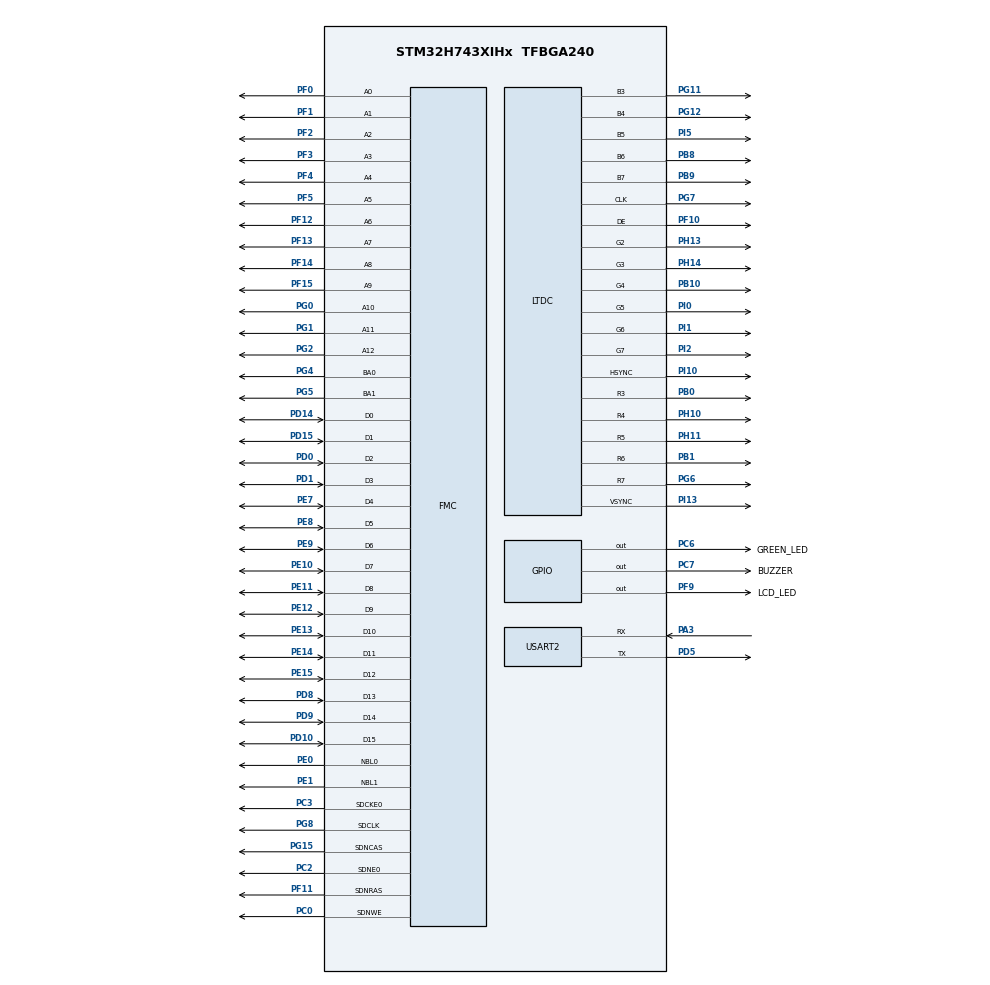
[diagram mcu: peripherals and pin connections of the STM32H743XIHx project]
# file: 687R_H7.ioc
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CORTEX_M7.AccessPermission-Cortex_Memory_Protection_Unit_Region1_Settings=MPU_REGION_FULL_ACCESS
CORTEX_M7.AccessPermission-Cortex_Memory_Protection_Unit_Region2_Settings=MPU_REGION_FULL_ACCESS
CORTEX_M7.AccessPermission-Cortex_Memory_Protection_Unit_Region3_Settings=MPU_REGION_FULL_ACCESS
CORTEX_M7.AccessPermission-Cortex_Memory_Protection_Unit_Region4_Settings=MPU_REGION_FULL_ACCESS
CORTEX_M7.BaseAddress-Cortex_Memory_Protection_Unit_Region1_Settings=0x30020000
CORTEX_M7.BaseAddress-Cortex_Memory_Protection_Unit_Region2_Settings=0x30040000
CORTEX_M7.BaseAddress-Cortex_Memory_Protection_Unit_Region3_Settings=0x60000000
CORTEX_M7.BaseAddress-Cortex_Memory_Protection_Unit_Region4_Settings=0x90000000
CORTEX_M7.CPU_DCache=Enabled
CORTEX_M7.CPU_ICache=Enabled
CORTEX_M7.DisableExec-Cortex_Memory_Protection_Unit_Region0_Settings=MPU_INSTRUCTION_ACCESS_DISABLE
CORTEX_M7.DisableExec-Cortex_Memory_Protection_Unit_Region1_Settings=MPU_INSTRUCTION_ACCESS_DISABLE
CORTEX_M7.DisableExec-Cortex_Memory_Protection_Unit_Region2_Settings=MPU_INSTRUCTION_ACCESS_DISABLE
CORTEX_M7.DisableExec-Cortex_Memory_Protection_Unit_Region3_Settings=MPU_INSTRUCTION_ACCESS_DISABLE
CORTEX_M7.Enable-Cortex_Memory_Protection_Unit_Region0_Settings=MPU_REGION_ENABLE
CORTEX_M7.Enable-Cortex_Memory_Protection_Unit_Region1_Settings=MPU_REGION_ENABLE
CORTEX_M7.Enable-Cortex_Memory_Protection_Unit_Region2_Settings=MPU_REGION_ENABLE
CORTEX_M7.Enable-Cortex_Memory_Protection_Unit_Region3_Settings=MPU_REGION_ENABLE
CORTEX_M7.Enable-Cortex_Memory_Protection_Unit_Region4_Settings=MPU_REGION_ENABLE
CORTEX_M7.IsBufferable-Cortex_Memory_Protection_Unit_Region2_Settings=MPU_ACCESS_BUFFERABLE
CORTEX_M7.IsBufferable-Cortex_Memory_Protection_Unit_Region3_Settings=MPU_ACCESS_BUFFERABLE
CORTEX_M7.IsBufferable-Cortex_Memory_Protection_Unit_Region4_Settings=MPU_ACCESS_BUFFERABLE
CORTEX_M7.IsCacheable-Cortex_Memory_Protection_Unit_Region3_Settings=MPU_ACCESS_CACHEABLE
CORTEX_M7.IsCacheable-Cortex_Memory_Protection_Unit_Region4_Settings=MPU_ACCESS_CACHEABLE
CORTEX_M7.IsShareable-Cortex_Memory_Protection_Unit_Region0_Settings=MPU_ACCESS_SHAREABLE
CORTEX_M7.IsShareable-Cortex_Memory_Protection_Unit_Region2_Settings=MPU_ACCESS_SHAREABLE
CORTEX_M7.IsShareable-Cortex_Memory_Protection_Unit_Region4_Settings=MPU_ACCESS_SHAREABLE
CORTEX_M7.MPU_Control=MPU_PRIVILEGED_DEFAULT
CORTEX_M7.Size-Cortex_Memory_Protection_Unit_Region0_Settings=MPU_REGION_SIZE_4GB
CORTEX_M7.Size-Cortex_Memory_Protection_Unit_Region1_Settings=MPU_REGION_SIZE_128B
CORTEX_M7.Size-Cortex_Memory_Protection_Unit_Region2_Settings=MPU_REGION_SIZE_512B
CORTEX_M7.Size-Cortex_Memory_Protection_Unit_Region3_Settings=MPU_REGION_SIZE_16MB
CORTEX_M7.Size-Cortex_Memory_Protection_Unit_Region4_Settings=MPU_REGION_SIZE_16MB
CORTEX_M7.SubRegionDisable-Cortex_Memory_Protection_Unit_Region0_Settings=0x87
CORTEX_M7.TypeExtField-Cortex_Memory_Protection_Unit_Region1_Settings=MPU_TEX_LEVEL1
CORTEX_M7.TypeExtField-Cortex_Memory_Protection_Unit_Region3_Settings=MPU_TEX_LEVEL1
CORTEX_M7.TypeExtField-Cortex_Memory_Protection_Unit_Region4_Settings=MPU_TEX_LEVEL1
CORTEX_M7.default_mode_Activation=0
DMA2D.ColorMode=DMA2D_OUTPUT_RGB565
DMA2D.Mode=DMA2D_R2M
FMC.BankMapConfig=FMC_SWAPBMAP_DISABLE
FMC.CASLatency1=FMC_SDRAM_CAS_LATENCY_3
FMC.ColumnBitsNumber1=FMC_SDRAM_COLUMN_BITS_NUM_9
FMC.ExitSelfRefreshDelay1=7
FMC.LoadToActiveDelay1=2
FMC.RCDDelay1=2
FMC.RPDelay1=2
FMC.ReadBurst1=FMC_SDRAM_RBURST_ENABLE
FMC.ReadPipeDelay1=FMC_SDRAM_RPIPE_DELAY_0
FMC.RowCycleDelay1=7
FMC.SDClockPeriod1=FMC_SDRAM_CLOCK_PERIOD_2
FMC.SelfRefreshTime1=4
FMC.WriteRecoveryTime1=3
LTDC.ActiveH=480
LTDC.ActiveW=800
LTDC.Alpha_L0=255
LTDC.BlendingFactor1_L0=LTDC_BLENDING_FACTOR1_CA
LTDC.BlendingFactor2_L0=LTDC_BLENDING_FACTOR2_CA
LTDC.Blue_L0=0
LTDC.DEPolarity=LTDC_DEPOLARITY_AL
LTDC.FBStartAdress_L0=0xC0000000
LTDC.Green_L0=0
LTDC.HBP=8
LTDC.HFP=8
LTDC.HSync=2
LTDC.ImageHeight_L0=480
LTDC.ImageWidth_L0=800
LTDC.Layers=0
LTDC.PCPolarity=LTDC_PCPOLARITY_IPC
LTDC.PixelFormat_L0=LTDC_PIXEL_FORMAT_RGB565
LTDC.Red=0
LTDC.Red_L0=0
LTDC.VBP=4
LTDC.VFP=8
LTDC.VSync=4
LTDC.WindowX1_L0=800
LTDC.WindowY1_L0=480
Mcu.Family=STM32H7
Mcu.Name=STM32H743XIHx
Mcu.Package=TFBGA240
NVIC.DMA2D_IRQn=true\:0\:0\:false\:false\:true\:true\:true\:true
NVIC.LTDC_ER_IRQn=true\:0\:0\:false\:false\:true\:true\:true\:true
NVIC.LTDC_IRQn=true\:0\:0\:false\:false\:true\:true\:true\:true
NVIC.PriorityGroup=NVIC_PRIORITYGROUP_4
NVIC.USART2_IRQn=true\:0\:0\:false\:false\:true\:true\:true\:true
PA13\ (JTMS/SWDIO).Mode=Serial_Wire
PA13\ (JTMS/SWDIO).Signal=DEBUG_JTMS-SWDIO
PA14\ (JTCK/SWCLK).Mode=Serial_Wire
PA14\ (JTCK/SWCLK).Signal=DEBUG_JTCK-SWCLK
PA3.Mode=Asynchronous
PA3.Signal=USART2_RX
PB0.GPIO_Speed=GPIO_SPEED_FREQ_VERY_HIGH
PB0.Mode=RGB565
PB0.Signal=LTDC_R3
PB1.GPIO_Speed=GPIO_SPEED_FREQ_VERY_HIGH
PB1.Mode=RGB565
PB1.Signal=LTDC_R6
PB10.GPIO_Speed=GPIO_SPEED_FREQ_VERY_HIGH
PB10.Mode=RGB565
PB10.Signal=LTDC_G4
PB8.GPIO_FM8=__NULL
PB8.GPIO_Speed=GPIO_SPEED_FREQ_VERY_HIGH
PB8.Mode=RGB565
PB8.Signal=LTDC_B6
PB9.GPIO_Speed=GPIO_SPEED_FREQ_VERY_HIGH
PB9.Mode=RGB565
PB9.Signal=LTDC_B7
PC0.Signal=FMC_SDNWE
PC2.Mode=SdramChipSelect1_1
PC2.Signal=FMC_SDNE0
PC3.Mode=SdramChipSelect1_1
PC3.Signal=FMC_SDCKE0
PC6.GPIO_Label=GREEN_LED
PC6.GPIO_PuPd=GPIO_PULLUP
PC6.PinState=GPIO_PIN_SET
PC6.Signal=GPIO_Output
PC7.GPIO_Label=BUZZER
PC7.GPIO_Speed=GPIO_SPEED_FREQ_HIGH
PC7.PinState=GPIO_PIN_SET
PC7.Signal=GPIO_Output
PD0.Signal=FMC_D2_DA2
PD1.Signal=FMC_D3_DA3
PD10.Signal=FMC_D15_DA15
PD14.Signal=FMC_D0_DA0
PD15.Signal=FMC_D1_DA1
PD5.Mode=Asynchronous
PD5.Signal=USART2_TX
PD8.Signal=FMC_D13_DA13
PD9.Signal=FMC_D14_DA14
PE0.Signal=FMC_NBL0
PE1.Signal=FMC_NBL1
PE10.Signal=FMC_D7_DA7
PE11.Signal=FMC_D8_DA8
PE12.Signal=FMC_D9_DA9
PE13.Signal=FMC_D10_DA10
PE14.Signal=FMC_D11_DA11
PE15.Signal=FMC_D12_DA12
PE7.Signal=FMC_D4_DA4
PE8.Signal=FMC_D5_DA5
PE9.Signal=FMC_D6_DA6
PF0.Signal=FMC_A0
PF1.Signal=FMC_A1
PF10.GPIO_Speed=GPIO_SPEED_FREQ_VERY_HIGH
PF10.Mode=RGB565
PF10.Signal=LTDC_DE
PF11.Signal=FMC_SDNRAS
PF12.Signal=FMC_A6
PF13.Signal=FMC_A7
PF14.Signal=FMC_A8
PF15.Signal=FMC_A9
PF2.Signal=FMC_A2
PF3.Signal=FMC_A3
PF4.Signal=FMC_A4
PF5.Signal=FMC_A5
PF9.GPIO_Label=LCD_LED
PF9.GPIO_PuPd=GPIO_PULLUP
PF9.PinState=GPIO_PIN_SET
PF9.Signal=GPIO_Output
PG0.Signal=FMC_A10
PG1.Signal=FMC_A11
PG11.GPIO_Speed=GPIO_SPEED_FREQ_VERY_HIGH
PG11.Mode=RGB565
PG11.Signal=LTDC_B3
PG12.GPIO_Speed=GPIO_SPEED_FREQ_VERY_HIGH
PG12.Mode=RGB565
PG12.Signal=LTDC_B4
PG15.Signal=FMC_SDNCAS
PG2.Signal=FMC_A12
PG4.Signal=FMC_A14_BA0
PG5.Signal=FMC_A15_BA1
PG6.GPIO_Speed=GPIO_SPEED_FREQ_VERY_HIGH
PG6.Mode=RGB565
PG6.Signal=LTDC_R7
PG7.GPIO_Speed=GPIO_SPEED_FREQ_VERY_HIGH
PG7.Mode=RGB565
PG7.Signal=LTDC_CLK
PG8.Signal=FMC_SDCLK
PH0-OSC_IN\ (PH0).Mode=HSE-External-Oscillator
PH0-OSC_IN\ (PH0).Signal=RCC_OSC_IN
PH1-OSC_OUT\ (PH1).Mode=HSE-External-Oscillator
PH1-OSC_OUT\ (PH1).Signal=RCC_OSC_OUT
PH10.GPIO_Speed=GPIO_SPEED_FREQ_VERY_HIGH
PH10.Mode=RGB565
PH10.Signal=LTDC_R4
PH11.GPIO_Speed=GPIO_SPEED_FREQ_VERY_HIGH
PH11.Mode=RGB565
PH11.Signal=LTDC_R5
PH13.GPIO_Speed=GPIO_SPEED_FREQ_VERY_HIGH
PH13.Mode=RGB565
PH13.Signal=LTDC_G2
PH14.GPIO_Speed=GPIO_SPEED_FREQ_VERY_HIGH
PH14.Mode=RGB565
PH14.Signal=LTDC_G3
PI0.GPIO_Speed=GPIO_SPEED_FREQ_VERY_HIGH
PI0.Mode=RGB565
PI0.Signal=LTDC_G5
PI1.GPIO_Speed=GPIO_SPEED_FREQ_VERY_HIGH
PI1.Mode=RGB565
PI1.Signal=LTDC_G6
PI10.GPIO_Speed=GPIO_SPEED_FREQ_VERY_HIGH
PI10.Mode=RGB565
PI10.Signal=LTDC_HSYNC
PI13.GPIO_Speed=GPIO_SPEED_FREQ_VERY_HIGH
PI13.Mode=RGB565
PI13.Signal=LTDC_VSYNC
PI2.GPIO_Speed=GPIO_SPEED_FREQ_VERY_HIGH
PI2.Mode=RGB565
PI2.Signal=LTDC_G7
PI5.GPIO_Speed=GPIO_SPEED_FREQ_VERY_HIGH
PI5.Mode=RGB565
PI5.Signal=LTDC_B5
ProjectManager.HeapSize=0x2000
ProjectManager.StackSize=0x1000
ProjectManager.TargetToolchain=STM32CubeIDE
RCC.ADCFreq_Value=100000000
RCC.APB1Freq_Value=120000000
RCC.APB2Freq_Value=120000000
RCC.APB3Freq_Value=120000000
RCC.APB4Freq_Value=120000000
RCC.CortexFreq_Value=240000000
RCC.DIVM1=1
RCC.DIVM2=1
RCC.DIVM3=1
RCC.DIVN1=60
RCC.DIVN2=25
RCC.DIVN3=24
RCC.DIVR2=1
RCC.DIVR3=6
RCC.FMCCLockSelection=RCC_FMCCLKSOURCE_PLL2
RCC.HCLKFreq_Value=120000000
RCC.HPRE=RCC_HCLK_DIV2
RCC.HSE_VALUE=8000000
RCC.PLL2FRACN=0
RCC.PLL3FRACN=0
RCC.PLLFRACN=0
RCC.PLLSourceVirtual=RCC_PLLSOURCE_HSE
RCC.PWR_Regulator_Voltage_Scale=PWR_REGULATOR_VOLTAGE_SCALE0
RCC.SYSCLKFreq_VALUE=240000000
RCC.SYSCLKSource=RCC_SYSCLKSOURCE_PLLCLK
RCC.USART234578CLockSelection=RCC_USART234578CLKSOURCE_CSI
RCC.USBFreq_Value=240000000
SH.FMC_A0.0=FMC_A0,13b-sda1
SH.FMC_A1.0=FMC_A1,13b-sda1
SH.FMC_A10.0=FMC_A10,13b-sda1
SH.FMC_A11.0=FMC_A11,13b-sda1
SH.FMC_A12.0=FMC_A12,13b-sda1
SH.FMC_A14_BA0.0=FMC_BA0,FourSdramBanks1
SH.FMC_A15_BA1.0=FMC_BA1,FourSdramBanks1
SH.FMC_A2.0=FMC_A2,13b-sda1
SH.FMC_A3.0=FMC_A3,13b-sda1
SH.FMC_A4.0=FMC_A4,13b-sda1
SH.FMC_A5.0=FMC_A5,13b-sda1
SH.FMC_A6.0=FMC_A6,13b-sda1
SH.FMC_A7.0=FMC_A7,13b-sda1
SH.FMC_A8.0=FMC_A8,13b-sda1
SH.FMC_A9.0=FMC_A9,13b-sda1
SH.FMC_D0_DA0.0=FMC_D0,sd-16b-d1
SH.FMC_D10_DA10.0=FMC_D10,sd-16b-d1
SH.FMC_D11_DA11.0=FMC_D11,sd-16b-d1
SH.FMC_D12_DA12.0=FMC_D12,sd-16b-d1
SH.FMC_D13_DA13.0=FMC_D13,sd-16b-d1
SH.FMC_D14_DA14.0=FMC_D14,sd-16b-d1
SH.FMC_D15_DA15.0=FMC_D15,sd-16b-d1
SH.FMC_D1_DA1.0=FMC_D1,sd-16b-d1
SH.FMC_D2_DA2.0=FMC_D2,sd-16b-d1
SH.FMC_D3_DA3.0=FMC_D3,sd-16b-d1
SH.FMC_D4_DA4.0=FMC_D4,sd-16b-d1
SH.FMC_D5_DA5.0=FMC_D5,sd-16b-d1
SH.FMC_D6_DA6.0=FMC_D6,sd-16b-d1
SH.FMC_D7_DA7.0=FMC_D7,sd-16b-d1
SH.FMC_D8_DA8.0=FMC_D8,sd-16b-d1
SH.FMC_D9_DA9.0=FMC_D9,sd-16b-d1
SH.FMC_NBL0.0=FMC_NBL0,Sd2ByteEnable1
SH.FMC_NBL1.0=FMC_NBL1,Sd2ByteEnable1
SH.FMC_SDCLK.0=FMC_SDCLK,13b-sda1
SH.FMC_SDNCAS.0=FMC_SDNCAS,13b-sda1
SH.FMC_SDNRAS.0=FMC_SDNRAS,13b-sda1
SH.FMC_SDNWE.0=FMC_SDNWE,13b-sda1
STMicroelectronics.X-CUBE-TOUCHGFX.4.25.0.ApplicationCcGraphicsJjApplication=TouchGFXOoGenerator
STMicroelectronics.X-CUBE-TOUCHGFX.4.25.0.tgfx_address1=0xC0000000
STMicroelectronics.X-CUBE-TOUCHGFX.4.25.0.tgfx_address2=0xC0800000
STMicroelectronics.X-CUBE-TOUCHGFX.4.25.0.tgfx_buffering_strategy=Double
STMicroelectronics.X-CUBE-TOUCHGFX.4.25.0.tgfx_display_interface=disp_ltdc
STMicroelectronics.X-CUBE-TOUCHGFX.4.25.0.tgfx_hardware_accelerator=dma_2d
STMicroelectronics.X-CUBE-TOUCHGFX.4.25.0.tgfx_location=By Address
STMicroelectronics.X-CUBE-TOUCHGFX.4.25.0.tgfx_vsync=vsync_ltdc
STMicroelectronics.X-CUBE-TOUCHGFX.4.25.0_IsPackSelfContextualization=true
USART2.VirtualMode-Asynchronous=VM_ASYNC
VP_CRC_VS_CRC.Mode=CRC_Activate
VP_DMA2D_VS_DMA2D.Mode=DMA2D_Activate
VP_MEMORYMAP_VS_MEMORYMAP.Mode=CurAppReg
VP_STMicroelectronics.X-CUBE-TOUCHGFX_VS_GraphicsJjApplication_4.25.0.Mode=GraphicsJjApplication
board=custom

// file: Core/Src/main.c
/* USER CODE BEGIN Header */
/**
  ******************************************************************************
  * @file           : main.c
  * @brief          : Main program body
  ******************************************************************************
  * @attention
  *
  * Copyright (c) 2025 STMicroelectronics.
  * All rights reserved.
  *
  * This software is licensed under terms that can be found in the LICENSE file
  * in the root directory of this software component.
  * If no LICENSE file comes with this software, it is provided AS-IS.
  *
  ******************************************************************************
  */
/* USER CODE END Header */
#include "main.h"
#include "crc.h"
#include "dma2d.h"
#include "ltdc.h"
#include "usart.h"
#include "gpio.h"
#include "fmc.h"
#include "app_touchgfx.h"

/* USER CODE BEGIN Includes */
#include "../../Application/MainApplication.hpp"
/* USER CODE END Includes */

void SystemClock_Config(void);
static void MPU_Config(void);

int main(void)
{

  /* MPU Configuration--------------------------------------------------------*/
  MPU_Config();

  /* Enable the CPU Cache */

  /* Enable I-Cache---------------------------------------------------------*/
  SCB_EnableICache();

  /* Enable D-Cache---------------------------------------------------------*/
  SCB_EnableDCache();

  /* MCU Configuration--------------------------------------------------------*/

  /* Reset of all peripherals, Initializes the Flash interface and the Systick. */
  HAL_Init();

  /* Configure the system clock */
  SystemClock_Config();

  /* Initialize all configured peripherals */
  MX_GPIO_Init();
  MX_LTDC_Init();
  MX_CRC_Init();
  MX_FMC_Init();
  MX_DMA2D_Init();
  MX_USART2_UART_Init();
  MX_TouchGFX_Init();

  /* Infinite loop */
  /* USER CODE BEGIN WHILE */
  MainApplicationInit();
  while (1)
  {
    /* USER CODE END WHILE */

  MX_TouchGFX_Process();
    /* USER CODE BEGIN 3 */
  MainApplicationLoop();
  }
  /* USER CODE END 3 */
}

void SystemClock_Config(void)
{
  RCC_OscInitTypeDef RCC_OscInitStruct = {0};
  RCC_ClkInitTypeDef RCC_ClkInitStruct = {0};

  /** Supply configuration update enable
  */
  HAL_PWREx_ConfigSupply(PWR_LDO_SUPPLY);

  /** Configure the main internal regulator output voltage
  */
  __HAL_PWR_VOLTAGESCALING_CONFIG(PWR_REGULATOR_VOLTAGE_SCALE0);

  while(!__HAL_PWR_GET_FLAG(PWR_FLAG_VOSRDY)) {}

  /** Initializes the RCC Oscillators according to the specified parameters
  * in the RCC_OscInitTypeDef structure.
  */
  RCC_OscInitStruct.OscillatorType = RCC_OSCILLATORTYPE_CSI|RCC_OSCILLATORTYPE_HSE;
  RCC_OscInitStruct.HSEState = RCC_HSE_ON;
  RCC_OscInitStruct.CSIState = RCC_CSI_ON;
  RCC_OscInitStruct.CSICalibrationValue = RCC_CSICALIBRATION_DEFAULT;
  RCC_OscInitStruct.PLL.PLLState = RCC_PLL_ON;
  RCC_OscInitStruct.PLL.PLLSource = RCC_PLLSOURCE_HSE;
  RCC_OscInitStruct.PLL.PLLM = 1;
  RCC_OscInitStruct.PLL.PLLN = 60;
  RCC_OscInitStruct.PLL.PLLP = 2;
  RCC_OscInitStruct.PLL.PLLQ = 2;
  RCC_OscInitStruct.PLL.PLLR = 2;
  RCC_OscInitStruct.PLL.PLLRGE = RCC_PLL1VCIRANGE_3;
  RCC_OscInitStruct.PLL.PLLVCOSEL = RCC_PLL1VCOWIDE;
  RCC_OscInitStruct.PLL.PLLFRACN = 0;
  if (HAL_RCC_OscConfig(&RCC_OscInitStruct) != HAL_OK)
  {
    Error_Handler();
  }

  /** Initializes the CPU, AHB and APB buses clocks
  */
  RCC_ClkInitStruct.ClockType = RCC_CLOCKTYPE_HCLK|RCC_CLOCKTYPE_SYSCLK
                              |RCC_CLOCKTYPE_PCLK1|RCC_CLOCKTYPE_PCLK2
                              |RCC_CLOCKTYPE_D3PCLK1|RCC_CLOCKTYPE_D1PCLK1;
  RCC_ClkInitStruct.SYSCLKSource = RCC_SYSCLKSOURCE_PLLCLK;
  RCC_ClkInitStruct.SYSCLKDivider = RCC_SYSCLK_DIV1;
  RCC_ClkInitStruct.AHBCLKDivider = RCC_HCLK_DIV2;
  RCC_ClkInitStruct.APB3CLKDivider = RCC_APB3_DIV1;
  RCC_ClkInitStruct.APB1CLKDivider = RCC_APB1_DIV1;
  RCC_ClkInitStruct.APB2CLKDivider = RCC_APB2_DIV1;
  RCC_ClkInitStruct.APB4CLKDivider = RCC_APB4_DIV1;

  if (HAL_RCC_ClockConfig(&RCC_ClkInitStruct, FLASH_LATENCY_1) != HAL_OK)
  {
    Error_Handler();
  }
}

 /* MPU Configuration */

void MPU_Config(void)
{
  MPU_Region_InitTypeDef MPU_InitStruct = {0};

  /* Disables the MPU */
  HAL_MPU_Disable();

  /** Initializes and configures the Region and the memory to be protected
  */
  MPU_InitStruct.Enable = MPU_REGION_ENABLE;
  MPU_InitStruct.Number = MPU_REGION_NUMBER0;
  MPU_InitStruct.BaseAddress = 0x0;
  MPU_InitStruct.Size = MPU_REGION_SIZE_4GB;
  MPU_InitStruct.SubRegionDisable = 0x87;
  MPU_InitStruct.TypeExtField = MPU_TEX_LEVEL0;
  MPU_InitStruct.AccessPermission = MPU_REGION_NO_ACCESS;
  MPU_InitStruct.DisableExec = MPU_INSTRUCTION_ACCESS_DISABLE;
  MPU_InitStruct.IsShareable = MPU_ACCESS_SHAREABLE;
  MPU_InitStruct.IsCacheable = MPU_ACCESS_NOT_CACHEABLE;
  MPU_InitStruct.IsBufferable = MPU_ACCESS_NOT_BUFFERABLE;

  HAL_MPU_ConfigRegion(&MPU_InitStruct);

  /** Initializes and configures the Region and the memory to be protected
  */
  MPU_InitStruct.Number = MPU_REGION_NUMBER1;
  MPU_InitStruct.BaseAddress = 0x30020000;
  MPU_InitStruct.Size = MPU_REGION_SIZE_128B;
  MPU_InitStruct.SubRegionDisable = 0x0;
  MPU_InitStruct.TypeExtField = MPU_TEX_LEVEL1;
  MPU_InitStruct.AccessPermission = MPU_REGION_FULL_ACCESS;
  MPU_InitStruct.IsShareable = MPU_ACCESS_NOT_SHAREABLE;

  HAL_MPU_ConfigRegion(&MPU_InitStruct);

  /** Initializes and configures the Region and the memory to be protected
  */
  MPU_InitStruct.Number = MPU_REGION_NUMBER2;
  MPU_InitStruct.BaseAddress = 0x30040000;
  MPU_InitStruct.Size = MPU_REGION_SIZE_512B;
  MPU_InitStruct.TypeExtField = MPU_TEX_LEVEL0;
  MPU_InitStruct.IsShareable = MPU_ACCESS_SHAREABLE;
  MPU_InitStruct.IsBufferable = MPU_ACCESS_BUFFERABLE;

  HAL_MPU_ConfigRegion(&MPU_InitStruct);

  /** Initializes and configures the Region and the memory to be protected
  */
  MPU_InitStruct.Number = MPU_REGION_NUMBER3;
  MPU_InitStruct.BaseAddress = 0x60000000;
  MPU_InitStruct.Size = MPU_REGION_SIZE_16MB;
  MPU_InitStruct.TypeExtField = MPU_TEX_LEVEL1;
  MPU_InitStruct.IsShareable = MPU_ACCESS_NOT_SHAREABLE;
  MPU_InitStruct.IsCacheable = MPU_ACCESS_CACHEABLE;

  HAL_MPU_ConfigRegion(&MPU_InitStruct);

  /** Initializes and configures the Region and the memory to be protected
  */
  MPU_InitStruct.Number = MPU_REGION_NUMBER4;
  MPU_InitStruct.BaseAddress = 0x90000000;
  MPU_InitStruct.DisableExec = MPU_INSTRUCTION_ACCESS_ENABLE;
  MPU_InitStruct.IsShareable = MPU_ACCESS_SHAREABLE;

  HAL_MPU_ConfigRegion(&MPU_InitStruct);
  /* Enables the MPU */
  HAL_MPU_Enable(MPU_PRIVILEGED_DEFAULT);

}

void Error_Handler(void)
{
  __disable_irq();
  while (1)
  {
  }
}
